VERSION ""

NS_ :

BS_:
BU_: Main Communication
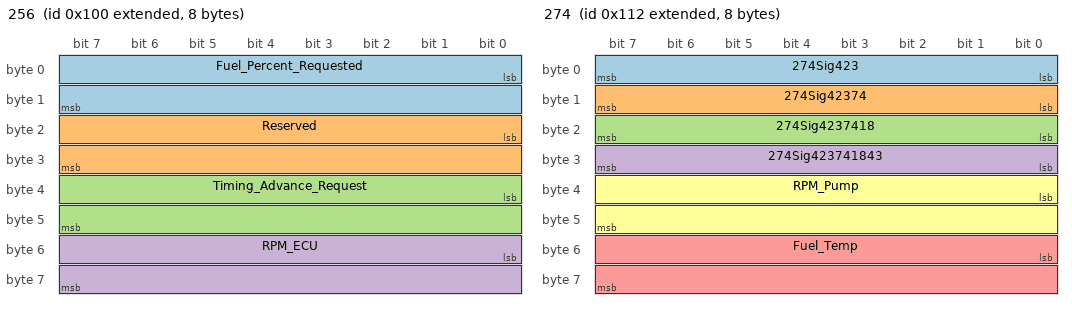
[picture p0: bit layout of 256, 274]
BO_ 2147483904 256: 8 Main Communication
   SG_ Fuel_Percent_Requested : 0|16@1+ (0.024414,0) [0|100] "%" Main Communication
   SG_ Reserved : 16|16@1+ (0.024414,0) [0|100] "%" Main Communication
   SG_ Timing_Advance_Request : 32|16@1+ (0.0078125,0) [0|100] "Degrees" Main Communication
   SG_ RPM_ECU : 48|16@1+ (0.25,0) [0|4000] "RPM" Main Communication

BO_ 2147483649 1280: 8 Main Communication

BO_ 2147483922 274: 8 Main Communication
   SG_ 274Sig423 : 0|8@1+ (1,0) [0|1] "" Main Communication
   SG_ 274Sig42374 : 8|8@1+ (1,0) [0|1] "" Main Communication
   SG_ 274Sig4237418 : 16|8@1+ (1,0) [0|1] "" Main Communication
   SG_ 274Sig423741843 : 24|8@1+ (1,0) [0|1] "" Main Communication
   SG_ Fuel_Temp : 48|16@1+ (0.0625,0) [0|5000] "Kelvin" Main Communication
   SG_ RPM_Pump : 32|16@1+ (0.25,0) [0|1] "RPM" Main Communication

BO_ 2147483651 1298: 8 Main Communication

CM_ BU_ Main Communication "Default node if none specified";
CM_ SG_ 2147483904 Fuel_Percent_Requested "Fuel_Percent_Requested";
CM_ SG_ 2147483904 Reserved "RPM";
CM_ SG_ 2147483904 Timing_Advance_Request "128_bits_per_degree";
CM_ SG_ 2147483904 RPM_ECU "RPM";
CM_ BO_ 2147483922 "Pump to ECU";
BA_DEF_ BO_ "GenMsgBackgroundColor" STRING ;
BA_DEF_ BO_ "GenMsgForegroundColor" STRING ;
BA_DEF_ BO_ "filterlabeling" INT 0 0;
BA_DEF_DEF_ "GenMsgBackgroundColor" "#ffffff";
BA_DEF_DEF_ "GenMsgForegroundColor" "#000000";
BA_DEF_DEF_ "filterlabeling" 1;
